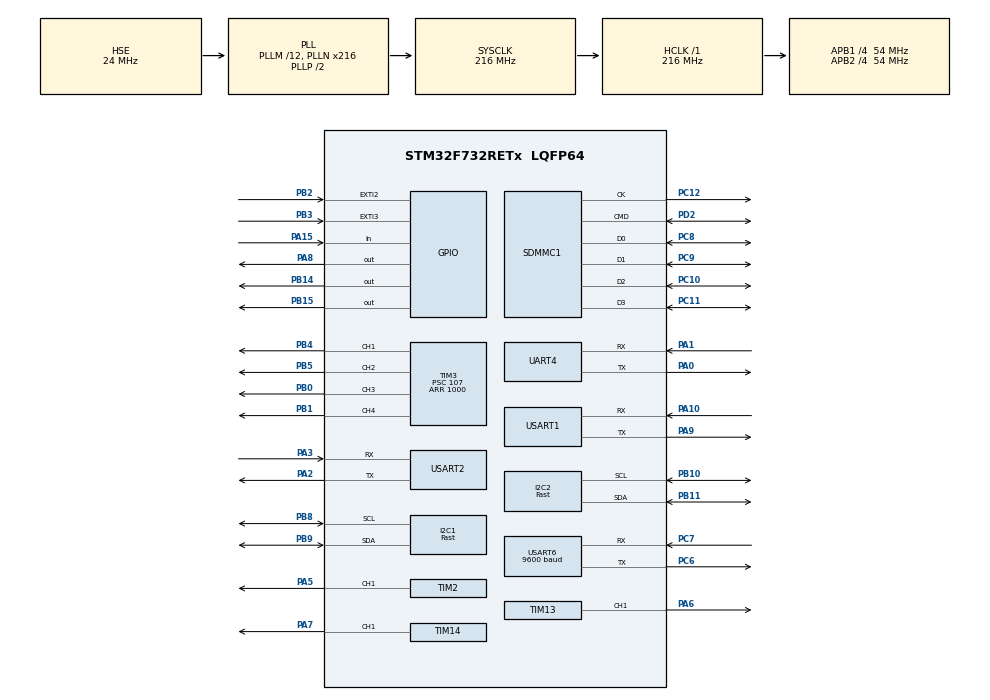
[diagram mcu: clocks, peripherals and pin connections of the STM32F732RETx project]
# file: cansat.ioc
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CORTEX_M7.default_mode_Activation=1
Dma.I2C1_RX.3.Direction=DMA_PERIPH_TO_MEMORY
Dma.I2C1_RX.3.FIFOMode=DMA_FIFOMODE_DISABLE
Dma.I2C1_RX.3.Instance=DMA1_Stream0
Dma.I2C1_RX.3.MemDataAlignment=DMA_MDATAALIGN_BYTE
Dma.I2C1_RX.3.MemInc=DMA_MINC_ENABLE
Dma.I2C1_RX.3.Mode=DMA_NORMAL
Dma.I2C1_RX.3.PeriphDataAlignment=DMA_PDATAALIGN_BYTE
Dma.I2C1_RX.3.PeriphInc=DMA_PINC_DISABLE
Dma.I2C1_RX.3.Priority=DMA_PRIORITY_HIGH
Dma.I2C2_RX.4.Direction=DMA_PERIPH_TO_MEMORY
Dma.I2C2_RX.4.FIFOMode=DMA_FIFOMODE_DISABLE
Dma.I2C2_RX.4.Instance=DMA1_Stream3
Dma.I2C2_RX.4.MemDataAlignment=DMA_MDATAALIGN_BYTE
Dma.I2C2_RX.4.MemInc=DMA_MINC_ENABLE
Dma.I2C2_RX.4.Mode=DMA_NORMAL
Dma.I2C2_RX.4.PeriphDataAlignment=DMA_PDATAALIGN_BYTE
Dma.I2C2_RX.4.PeriphInc=DMA_PINC_DISABLE
Dma.I2C2_RX.4.Priority=DMA_PRIORITY_VERY_HIGH
Dma.Request0=UART4_RX
Dma.Request1=USART1_RX
Dma.Request2=USART1_TX
Dma.Request3=I2C1_RX
Dma.Request4=I2C2_RX
Dma.Request5=SDMMC1_RX
Dma.Request6=SDMMC1_TX
Dma.Request7=USART6_RX
Dma.SDMMC1_RX.5.Direction=DMA_PERIPH_TO_MEMORY
Dma.SDMMC1_RX.5.FIFOMode=DMA_FIFOMODE_ENABLE
Dma.SDMMC1_RX.5.FIFOThreshold=DMA_FIFO_THRESHOLD_FULL
Dma.SDMMC1_RX.5.Instance=DMA2_Stream3
Dma.SDMMC1_RX.5.MemBurst=DMA_MBURST_INC4
Dma.SDMMC1_RX.5.MemDataAlignment=DMA_MDATAALIGN_WORD
Dma.SDMMC1_RX.5.MemInc=DMA_MINC_ENABLE
Dma.SDMMC1_RX.5.Mode=DMA_PFCTRL
Dma.SDMMC1_RX.5.PeriphBurst=DMA_PBURST_INC4
Dma.SDMMC1_RX.5.PeriphDataAlignment=DMA_PDATAALIGN_WORD
Dma.SDMMC1_RX.5.PeriphInc=DMA_PINC_DISABLE
Dma.SDMMC1_RX.5.Priority=DMA_PRIORITY_VERY_HIGH
Dma.SDMMC1_TX.6.Direction=DMA_MEMORY_TO_PERIPH
Dma.SDMMC1_TX.6.FIFOMode=DMA_FIFOMODE_ENABLE
Dma.SDMMC1_TX.6.FIFOThreshold=DMA_FIFO_THRESHOLD_FULL
Dma.SDMMC1_TX.6.Instance=DMA2_Stream6
Dma.SDMMC1_TX.6.MemBurst=DMA_MBURST_INC4
Dma.SDMMC1_TX.6.MemDataAlignment=DMA_MDATAALIGN_WORD
Dma.SDMMC1_TX.6.MemInc=DMA_MINC_ENABLE
Dma.SDMMC1_TX.6.Mode=DMA_PFCTRL
Dma.SDMMC1_TX.6.PeriphBurst=DMA_PBURST_INC4
Dma.SDMMC1_TX.6.PeriphDataAlignment=DMA_PDATAALIGN_WORD
Dma.SDMMC1_TX.6.PeriphInc=DMA_PINC_DISABLE
Dma.SDMMC1_TX.6.Priority=DMA_PRIORITY_VERY_HIGH
Dma.UART4_RX.0.Direction=DMA_PERIPH_TO_MEMORY
Dma.UART4_RX.0.FIFOMode=DMA_FIFOMODE_DISABLE
Dma.UART4_RX.0.Instance=DMA1_Stream2
Dma.UART4_RX.0.MemDataAlignment=DMA_MDATAALIGN_BYTE
Dma.UART4_RX.0.MemInc=DMA_MINC_ENABLE
Dma.UART4_RX.0.Mode=DMA_NORMAL
Dma.UART4_RX.0.PeriphDataAlignment=DMA_PDATAALIGN_BYTE
Dma.UART4_RX.0.PeriphInc=DMA_PINC_DISABLE
Dma.UART4_RX.0.Priority=DMA_PRIORITY_MEDIUM
Dma.USART1_RX.1.Direction=DMA_PERIPH_TO_MEMORY
Dma.USART1_RX.1.FIFOMode=DMA_FIFOMODE_DISABLE
Dma.USART1_RX.1.Instance=DMA2_Stream2
Dma.USART1_RX.1.MemDataAlignment=DMA_MDATAALIGN_BYTE
Dma.USART1_RX.1.MemInc=DMA_MINC_ENABLE
Dma.USART1_RX.1.Mode=DMA_NORMAL
Dma.USART1_RX.1.PeriphDataAlignment=DMA_PDATAALIGN_BYTE
Dma.USART1_RX.1.PeriphInc=DMA_PINC_DISABLE
Dma.USART1_RX.1.Priority=DMA_PRIORITY_HIGH
Dma.USART1_TX.2.Direction=DMA_MEMORY_TO_PERIPH
Dma.USART1_TX.2.FIFOMode=DMA_FIFOMODE_DISABLE
Dma.USART1_TX.2.Instance=DMA2_Stream7
Dma.USART1_TX.2.MemDataAlignment=DMA_MDATAALIGN_BYTE
Dma.USART1_TX.2.MemInc=DMA_MINC_ENABLE
Dma.USART1_TX.2.Mode=DMA_NORMAL
Dma.USART1_TX.2.PeriphDataAlignment=DMA_PDATAALIGN_BYTE
Dma.USART1_TX.2.PeriphInc=DMA_PINC_DISABLE
Dma.USART1_TX.2.Priority=DMA_PRIORITY_MEDIUM
Dma.USART6_RX.7.Direction=DMA_PERIPH_TO_MEMORY
Dma.USART6_RX.7.FIFOMode=DMA_FIFOMODE_DISABLE
Dma.USART6_RX.7.Instance=DMA2_Stream1
Dma.USART6_RX.7.MemDataAlignment=DMA_MDATAALIGN_BYTE
Dma.USART6_RX.7.MemInc=DMA_MINC_ENABLE
Dma.USART6_RX.7.Mode=DMA_NORMAL
Dma.USART6_RX.7.PeriphDataAlignment=DMA_PDATAALIGN_BYTE
Dma.USART6_RX.7.PeriphInc=DMA_PINC_DISABLE
Dma.USART6_RX.7.Priority=DMA_PRIORITY_MEDIUM
FATFS.USE_DMA_CODE_SD=1
I2C1.I2C_Speed_Mode=I2C_Fast
I2C1.Timing=0x6000030D
I2C2.I2C_Speed_Mode=I2C_Fast
I2C2.Timing=0x6000030D
Mcu.Family=STM32F7
Mcu.Name=STM32F732RETx
Mcu.Package=LQFP64
NVIC.DMA1_Stream0_IRQn=true\:10\:0\:true\:false\:true\:false\:true\:true
NVIC.DMA1_Stream2_IRQn=true\:10\:0\:true\:false\:true\:false\:true\:true
NVIC.DMA1_Stream3_IRQn=true\:10\:0\:true\:false\:true\:false\:true\:true
NVIC.DMA2_Stream1_IRQn=true\:0\:0\:false\:false\:true\:false\:true\:true
NVIC.DMA2_Stream2_IRQn=true\:10\:0\:true\:false\:true\:false\:true\:true
NVIC.DMA2_Stream3_IRQn=true\:10\:0\:true\:false\:true\:false\:true\:true
NVIC.DMA2_Stream6_IRQn=true\:10\:0\:true\:false\:true\:false\:true\:true
NVIC.DMA2_Stream7_IRQn=true\:10\:0\:true\:false\:true\:false\:true\:true
NVIC.EXTI2_IRQn=true\:0\:0\:false\:false\:true\:true\:true\:true
NVIC.EXTI3_IRQn=true\:0\:0\:false\:false\:true\:true\:true\:true
NVIC.I2C1_ER_IRQn=true\:0\:0\:true\:false\:true\:true\:true\:true
NVIC.I2C1_EV_IRQn=true\:8\:0\:true\:false\:true\:true\:true\:true
NVIC.I2C2_ER_IRQn=true\:0\:0\:false\:false\:true\:true\:true\:true
NVIC.I2C2_EV_IRQn=true\:9\:0\:true\:false\:true\:true\:true\:true
NVIC.PriorityGroup=NVIC_PRIORITYGROUP_4
NVIC.SDMMC1_IRQn=true\:0\:0\:false\:false\:true\:true\:true\:true
NVIC.UART4_IRQn=true\:0\:0\:false\:false\:true\:true\:true\:true
NVIC.USART1_IRQn=true\:0\:0\:false\:false\:true\:true\:true\:true
NVIC.USART2_IRQn=true\:0\:0\:false\:false\:true\:true\:true\:true
NVIC.USART6_IRQn=true\:0\:0\:false\:false\:true\:true\:true\:true
PA0-WKUP.Mode=Asynchronous
PA0-WKUP.Signal=UART4_TX
PA1.Mode=Asynchronous
PA1.Signal=UART4_RX
PA10.Mode=Asynchronous
PA10.Signal=USART1_RX
PA15.Signal=GPIO_Input
PA2.Mode=Asynchronous
PA2.Signal=USART2_TX
PA3.Mode=Asynchronous
PA3.Signal=USART2_RX
PA5.Signal=S_TIM2_CH1_ETR
PA6.Signal=S_TIM13_CH1
PA7.Signal=S_TIM14_CH1
PA8.Signal=GPIO_Output
PA9.Mode=Asynchronous
PA9.Signal=USART1_TX
PB0.Signal=S_TIM3_CH3
PB1.Signal=S_TIM3_CH4
PB10.GPIO_Pu=GPIO_PULLUP
PB10.Mode=I2C
PB10.Signal=I2C2_SCL
PB11.GPIO_Pu=GPIO_PULLUP
PB11.Mode=I2C
PB11.Signal=I2C2_SDA
PB14.Signal=GPIO_Output
PB15.Signal=GPIO_Output
PB2.Signal=GPXTI2
PB3.Signal=GPXTI3
PB4.Signal=S_TIM3_CH1
PB5.Signal=S_TIM3_CH2
PB8.GPIO_Pu=GPIO_PULLUP
PB8.Mode=I2C
PB8.Signal=I2C1_SCL
PB9.GPIO_Pu=GPIO_PULLUP
PB9.Mode=I2C
PB9.Signal=I2C1_SDA
PC10.GPIO_PuPd=GPIO_PULLUP
PC10.Mode=SD_4_bits_Wide_bus
PC10.Signal=SDMMC1_D2
PC11.GPIO_PuPd=GPIO_PULLUP
PC11.Mode=SD_4_bits_Wide_bus
PC11.Signal=SDMMC1_D3
PC12.GPIO_PuPd=GPIO_PULLUP
PC12.Mode=SD_4_bits_Wide_bus
PC12.Signal=SDMMC1_CK
PC6.Mode=Asynchronous
PC6.Signal=USART6_TX
PC7.Mode=Asynchronous
PC7.Signal=USART6_RX
PC8.GPIO_PuPd=GPIO_PULLUP
PC8.Mode=SD_4_bits_Wide_bus
PC8.Signal=SDMMC1_D0
PC9.GPIO_PuPd=GPIO_PULLUP
PC9.Mode=SD_4_bits_Wide_bus
PC9.Signal=SDMMC1_D1
PD2.GPIO_PuPd=GPIO_PULLUP
PD2.Mode=SD_4_bits_Wide_bus
PD2.Signal=SDMMC1_CMD
PH0-OSC_IN.Mode=HSE-External-Oscillator
PH0-OSC_IN.Signal=RCC_OSC_IN
PH1-OSC_OUT.Mode=HSE-External-Oscillator
PH1-OSC_OUT.Signal=RCC_OSC_OUT
ProjectManager.HeapSize=0x800
ProjectManager.StackSize=0x1200
ProjectManager.TargetToolchain=STM32CubeIDE
RCC.AHBFreq_Value=216000000
RCC.APB1CLKDivider=RCC_HCLK_DIV4
RCC.APB1Freq_Value=54000000
RCC.APB1TimFreq_Value=108000000
RCC.APB2CLKDivider=RCC_HCLK_DIV4
RCC.APB2Freq_Value=54000000
RCC.APB2TimFreq_Value=108000000
RCC.CortexFreq_Value=216000000
RCC.HCLKFreq_Value=216000000
RCC.HSE_VALUE=24000000
RCC.HSI_VALUE=16000000
RCC.LSE_VALUE=32768
RCC.PLL48CLockSelection=RCC_CLK48SOURCE_PLLSAIP
RCC.PLLM=12
RCC.PLLN=216
RCC.PLLQ=4
RCC.PLLSAIN=96
RCC.PLLSAIP=RCC_PLLSAIP_DIV4
RCC.PLLSourceVirtual=RCC_PLLSOURCE_HSE
RCC.SDMMCClockSelection=RCC_SDMMC1CLKSOURCE_CLK48
RCC.SYSCLKFreq_VALUE=216000000
RCC.SYSCLKSource=RCC_SYSCLKSOURCE_PLLCLK
RCC.USBFreq_Value=48000000
RCC.VCOOutputFreq_Value=432000000
SH.S_TIM13_CH1.0=TIM13_CH1,PWM Generation1 CH1
SH.S_TIM14_CH1.0=TIM14_CH1,PWM Generation1 CH1
SH.S_TIM2_CH1_ETR.0=TIM2_CH1,PWM Generation1 CH1
SH.S_TIM3_CH1.0=TIM3_CH1,PWM Generation1 CH1
SH.S_TIM3_CH2.0=TIM3_CH2,PWM Generation2 CH2
SH.S_TIM3_CH3.0=TIM3_CH3,PWM Generation3 CH3
SH.S_TIM3_CH4.0=TIM3_CH4,PWM Generation4 CH4
TIM13.Channel=TIM_CHANNEL_1
TIM13.Period=2500
TIM13.Prescaler=107
TIM14.Channel=TIM_CHANNEL_1
TIM14.Period=2500
TIM14.Prescaler=107
TIM2.Channel-PWM\ Generation1\ CH1=TIM_CHANNEL_1
TIM2.Period=2500
TIM2.Prescaler=107
TIM3.Channel-PWM\ Generation1\ CH1=TIM_CHANNEL_1
TIM3.Channel-PWM\ Generation2\ CH2=TIM_CHANNEL_2
TIM3.Channel-PWM\ Generation3\ CH3=TIM_CHANNEL_3
TIM3.Channel-PWM\ Generation4\ CH4=TIM_CHANNEL_4
TIM3.Period=1000
TIM3.Prescaler=107
TIM5.Prescaler=107
USART1.VirtualMode-Asynchronous=VM_ASYNC
USART2.VirtualMode-Asynchronous=VM_ASYNC
USART6.BaudRate=9600
USART6.Mode=MODE_TX_RX
USART6.RxPinLevelInvertParam=ADVFEATURE_RXINV_ENABLE
USART6.VirtualMode=VM_ASYNC
VP_FATFS_VS_SDIO.Mode=SDIO
VP_TIM13_VS_ClockSourceINT.Mode=Enable_Timer
VP_TIM14_VS_ClockSourceINT.Mode=Enable_Timer
VP_TIM2_VS_ClockSourceINT.Mode=Internal
VP_TIM4_VS_ClockSourceINT.Mode=Internal
VP_TIM5_VS_ClockSourceINT.Mode=Internal
board=custom

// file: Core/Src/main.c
/* USER CODE BEGIN Header */
/**
  ******************************************************************************
  * @file           : main.c
  * @brief          : Main program body
  ******************************************************************************
  * @attention
  *
  * Copyright (c) 2025 STMicroelectronics.
  * All rights reserved.
  *
  * This software is licensed under terms that can be found in the LICENSE file
  * in the root directory of this software component.
  * If no LICENSE file comes with this software, it is provided AS-IS.
  *
  ******************************************************************************
  */
/* USER CODE END Header */
#include "main.h"
#include "dma.h"
#include "fatfs.h"
#include "i2c.h"
#include "sdmmc.h"
#include "tim.h"
#include "usart.h"
#include "gpio.h"

/* USER CODE BEGIN Includes */
#include "Wrapper.hpp"
/* USER CODE END Includes */

void SystemClock_Config(void);
static void MPU_Config(void);

int main(void)
{

  /* MPU Configuration--------------------------------------------------------*/
  MPU_Config();

  /* MCU Configuration--------------------------------------------------------*/

  /* Reset of all peripherals, Initializes the Flash interface and the Systick. */
  HAL_Init();

  /* Configure the system clock */
  SystemClock_Config();

  /* Initialize all configured peripherals */
  MX_GPIO_Init();
  MX_DMA_Init();
  MX_I2C1_Init();
  MX_I2C2_Init();
  MX_SDMMC1_SD_Init();
  MX_TIM3_Init();
  MX_TIM13_Init();
  MX_TIM14_Init();
  MX_UART4_Init();
  MX_USART1_UART_Init();
  MX_USART2_UART_Init();
  MX_USART6_UART_Init();
  MX_TIM2_Init();
  MX_TIM4_Init();
  MX_TIM5_Init();
  MX_FATFS_Init();
  /* USER CODE BEGIN 2 */
init();
  /* USER CODE END 2 */

  /* Infinite loop */
  /* USER CODE BEGIN WHILE */
  while (1)
  {
	  loop();
    /* USER CODE END WHILE */

  }
}

void SystemClock_Config(void)
{
  RCC_OscInitTypeDef RCC_OscInitStruct = {0};
  RCC_ClkInitTypeDef RCC_ClkInitStruct = {0};

  /** Configure the main internal regulator output voltage
  */
  __HAL_RCC_PWR_CLK_ENABLE();
  __HAL_PWR_VOLTAGESCALING_CONFIG(PWR_REGULATOR_VOLTAGE_SCALE1);

  /** Initializes the RCC Oscillators according to the specified parameters
  * in the RCC_OscInitTypeDef structure.
  */
  RCC_OscInitStruct.OscillatorType = RCC_OSCILLATORTYPE_HSE;
  RCC_OscInitStruct.HSEState = RCC_HSE_ON;
  RCC_OscInitStruct.PLL.PLLState = RCC_PLL_ON;
  RCC_OscInitStruct.PLL.PLLSource = RCC_PLLSOURCE_HSE;
  RCC_OscInitStruct.PLL.PLLM = 12;
  RCC_OscInitStruct.PLL.PLLN = 216;
  RCC_OscInitStruct.PLL.PLLP = RCC_PLLP_DIV2;
  RCC_OscInitStruct.PLL.PLLQ = 4;
  if (HAL_RCC_OscConfig(&RCC_OscInitStruct) != HAL_OK)
  {
    Error_Handler();
  }

  /** Activate the Over-Drive mode
  */
  if (HAL_PWREx_EnableOverDrive() != HAL_OK)
  {
    Error_Handler();
  }

  /** Initializes the CPU, AHB and APB buses clocks
  */
  RCC_ClkInitStruct.ClockType = RCC_CLOCKTYPE_HCLK|RCC_CLOCKTYPE_SYSCLK
                              |RCC_CLOCKTYPE_PCLK1|RCC_CLOCKTYPE_PCLK2;
  RCC_ClkInitStruct.SYSCLKSource = RCC_SYSCLKSOURCE_PLLCLK;
  RCC_ClkInitStruct.AHBCLKDivider = RCC_SYSCLK_DIV1;
  RCC_ClkInitStruct.APB1CLKDivider = RCC_HCLK_DIV4;
  RCC_ClkInitStruct.APB2CLKDivider = RCC_HCLK_DIV4;

  if (HAL_RCC_ClockConfig(&RCC_ClkInitStruct, FLASH_LATENCY_7) != HAL_OK)
  {
    Error_Handler();
  }
}

 /* MPU Configuration */

void MPU_Config(void)
{
  MPU_Region_InitTypeDef MPU_InitStruct = {0};

  /* Disables the MPU */
  HAL_MPU_Disable();

  /** Initializes and configures the Region and the memory to be protected
  */
  MPU_InitStruct.Enable = MPU_REGION_ENABLE;
  MPU_InitStruct.Number = MPU_REGION_NUMBER0;
  MPU_InitStruct.BaseAddress = 0x0;
  MPU_InitStruct.Size = MPU_REGION_SIZE_4GB;
  MPU_InitStruct.SubRegionDisable = 0x87;
  MPU_InitStruct.TypeExtField = MPU_TEX_LEVEL0;
  MPU_InitStruct.AccessPermission = MPU_REGION_NO_ACCESS;
  MPU_InitStruct.DisableExec = MPU_INSTRUCTION_ACCESS_DISABLE;
  MPU_InitStruct.IsShareable = MPU_ACCESS_SHAREABLE;
  MPU_InitStruct.IsCacheable = MPU_ACCESS_NOT_CACHEABLE;
  MPU_InitStruct.IsBufferable = MPU_ACCESS_NOT_BUFFERABLE;

  HAL_MPU_ConfigRegion(&MPU_InitStruct);
  /* Enables the MPU */
  HAL_MPU_Enable(MPU_PRIVILEGED_DEFAULT);

}

void Error_Handler(void)
{
  __disable_irq();
  while (1)
  {
  }
}
